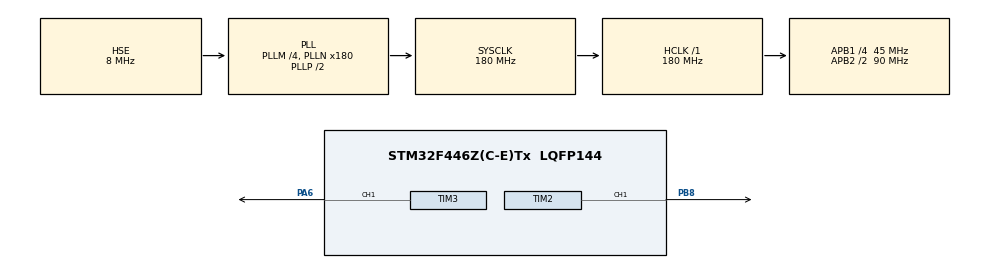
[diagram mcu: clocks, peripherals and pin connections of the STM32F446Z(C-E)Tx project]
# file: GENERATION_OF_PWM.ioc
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Mcu.Family=STM32F4
Mcu.Name=STM32F446Z(C-E)Tx
Mcu.Package=LQFP144
NVIC.PriorityGroup=NVIC_PRIORITYGROUP_4
PA6.Signal=S_TIM3_CH1
PB8.Signal=S_TIM2_CH1_ETR
PH0-OSC_IN.Mode=HSE-External-Oscillator
PH0-OSC_IN.Signal=RCC_OSC_IN
PH1-OSC_OUT.Mode=HSE-External-Oscillator
PH1-OSC_OUT.Signal=RCC_OSC_OUT
ProjectManager.HeapSize=0x200
ProjectManager.StackSize=0x400
ProjectManager.TargetToolchain=STM32CubeIDE
RCC.AHBFreq_Value=180000000
RCC.APB1CLKDivider=RCC_HCLK_DIV4
RCC.APB1Freq_Value=45000000
RCC.APB1TimFreq_Value=90000000
RCC.APB2CLKDivider=RCC_HCLK_DIV2
RCC.APB2Freq_Value=90000000
RCC.APB2TimFreq_Value=180000000
RCC.CortexFreq_Value=180000000
RCC.HCLKFreq_Value=180000000
RCC.HSE_VALUE=8000000
RCC.PLLM=4
RCC.PLLN=180
RCC.PLLSourceVirtual=RCC_PLLSOURCE_HSE
RCC.SYSCLKFreq_VALUE=180000000
RCC.SYSCLKSource=RCC_SYSCLKSOURCE_PLLCLK
RCC.USBFreq_Value=180000000
RCC.VCOOutputFreq_Value=360000000
SH.S_TIM2_CH1_ETR.0=TIM2_CH1,PWM Generation1 CH1
SH.S_TIM3_CH1.0=TIM3_CH1,PWM Generation1 CH1
TIM2.Channel-PWM\ Generation1\ CH1=TIM_CHANNEL_1
TIM2.Period=999
TIM2.Prescaler=179
TIM3.Channel-PWM\ Generation1\ CH1=TIM_CHANNEL_1
TIM3.Period=999
TIM3.Prescaler=179
VP_TIM2_VS_ClockSourceINT.Mode=Internal
VP_TIM3_VS_ClockSourceINT.Mode=Internal
board=custom

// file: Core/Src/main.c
/* USER CODE BEGIN Header */
/**
  ******************************************************************************
  * @file           : main.c
  * @brief          : Main program body
  ******************************************************************************
  * @attention
  *
  * Copyright (c) 2026 STMicroelectronics.
  * All rights reserved.
  *
  * This software is licensed under terms that can be found in the LICENSE file
  * in the root directory of this software component.
  * If no LICENSE file comes with this software, it is provided AS-IS.
  *
  ******************************************************************************
  */
/* USER CODE END Header */
#include "main.h"

TIM_HandleTypeDef htim2;
TIM_HandleTypeDef htim3;

/* USER CODE BEGIN PV */
int j;
/* USER CODE END PV */

void SystemClock_Config(void);
static void MX_GPIO_Init(void);
static void MX_TIM2_Init(void);
static void MX_TIM3_Init(void);

/* USER CODE BEGIN 0 */

	void Rotation(int i)
	{
		if(i>=0)
		{
			TIM2->CCR1 = i;
			TIM3->CCR1 = 0;
		}
		else
		{
			TIM3->CCR1 = 0;
			TIM3->CCR1 = -i;
		}
	}

/* USER CODE END 0 */

int main(void)
{

  /* MCU Configuration--------------------------------------------------------*/

  /* Reset of all peripherals, Initializes the Flash interface and the Systick. */
  HAL_Init();

  /* Configure the system clock */
  SystemClock_Config();

  /* Initialize all configured peripherals */
  MX_GPIO_Init();
  MX_TIM2_Init();
  MX_TIM3_Init();
  /* USER CODE BEGIN 2 */
	  HAL_TIM_PWM_Start(&htim2, TIM_CHANNEL_1);
	  HAL_TIM_PWM_Start(&htim3, TIM_CHANNEL_1);

  /* USER CODE END 2 */

  /* Infinite loop */
  while (1)
  {

    /* USER CODE BEGIN 3 */
	  Rotation(-100);
	  HAL_Delay(1000);
	  Rotation(100);
	  HAL_Delay(1000);
	  Rotation(0);
	  HAL_Delay(1000);
  }
  /* USER CODE END 3 */
}

void SystemClock_Config(void)
{
  RCC_OscInitTypeDef RCC_OscInitStruct = {0};
  RCC_ClkInitTypeDef RCC_ClkInitStruct = {0};

  /** Configure the main internal regulator output voltage
  */
  __HAL_RCC_PWR_CLK_ENABLE();
  __HAL_PWR_VOLTAGESCALING_CONFIG(PWR_REGULATOR_VOLTAGE_SCALE1);

  /** Initializes the RCC Oscillators according to the specified parameters
  * in the RCC_OscInitTypeDef structure.
  */
  RCC_OscInitStruct.OscillatorType = RCC_OSCILLATORTYPE_HSE;
  RCC_OscInitStruct.HSEState = RCC_HSE_ON;
  RCC_OscInitStruct.PLL.PLLState = RCC_PLL_ON;
  RCC_OscInitStruct.PLL.PLLSource = RCC_PLLSOURCE_HSE;
  RCC_OscInitStruct.PLL.PLLM = 4;
  RCC_OscInitStruct.PLL.PLLN = 180;
  RCC_OscInitStruct.PLL.PLLP = RCC_PLLP_DIV2;
  RCC_OscInitStruct.PLL.PLLQ = 2;
  RCC_OscInitStruct.PLL.PLLR = 2;
  if (HAL_RCC_OscConfig(&RCC_OscInitStruct) != HAL_OK)
  {
    Error_Handler();
  }

  /** Activate the Over-Drive mode
  */
  if (HAL_PWREx_EnableOverDrive() != HAL_OK)
  {
    Error_Handler();
  }

  /** Initializes the CPU, AHB and APB buses clocks
  */
  RCC_ClkInitStruct.ClockType = RCC_CLOCKTYPE_HCLK|RCC_CLOCKTYPE_SYSCLK
                              |RCC_CLOCKTYPE_PCLK1|RCC_CLOCKTYPE_PCLK2;
  RCC_ClkInitStruct.SYSCLKSource = RCC_SYSCLKSOURCE_PLLCLK;
  RCC_ClkInitStruct.AHBCLKDivider = RCC_SYSCLK_DIV1;
  RCC_ClkInitStruct.APB1CLKDivider = RCC_HCLK_DIV4;
  RCC_ClkInitStruct.APB2CLKDivider = RCC_HCLK_DIV2;

  if (HAL_RCC_ClockConfig(&RCC_ClkInitStruct, FLASH_LATENCY_5) != HAL_OK)
  {
    Error_Handler();
  }
}

static void MX_TIM2_Init(void)
{

  TIM_ClockConfigTypeDef sClockSourceConfig = {0};
  TIM_MasterConfigTypeDef sMasterConfig = {0};
  TIM_OC_InitTypeDef sConfigOC = {0};

  htim2.Instance = TIM2;
  htim2.Init.Prescaler = 179;
  htim2.Init.CounterMode = TIM_COUNTERMODE_UP;
  htim2.Init.Period = 999;
  htim2.Init.ClockDivision = TIM_CLOCKDIVISION_DIV1;
  htim2.Init.AutoReloadPreload = TIM_AUTORELOAD_PRELOAD_DISABLE;
  if (HAL_TIM_Base_Init(&htim2) != HAL_OK)
  {
    Error_Handler();
  }
  sClockSourceConfig.ClockSource = TIM_CLOCKSOURCE_INTERNAL;
  if (HAL_TIM_ConfigClockSource(&htim2, &sClockSourceConfig) != HAL_OK)
  {
    Error_Handler();
  }
  if (HAL_TIM_PWM_Init(&htim2) != HAL_OK)
  {
    Error_Handler();
  }
  sMasterConfig.MasterOutputTrigger = TIM_TRGO_RESET;
  sMasterConfig.MasterSlaveMode = TIM_MASTERSLAVEMODE_DISABLE;
  if (HAL_TIMEx_MasterConfigSynchronization(&htim2, &sMasterConfig) != HAL_OK)
  {
    Error_Handler();
  }
  sConfigOC.OCMode = TIM_OCMODE_PWM1;
  sConfigOC.Pulse = 0;
  sConfigOC.OCPolarity = TIM_OCPOLARITY_HIGH;
  sConfigOC.OCFastMode = TIM_OCFAST_DISABLE;
  if (HAL_TIM_PWM_ConfigChannel(&htim2, &sConfigOC, TIM_CHANNEL_1) != HAL_OK)
  {
    Error_Handler();
  }
  HAL_TIM_MspPostInit(&htim2);

}

static void MX_TIM3_Init(void)
{

  TIM_ClockConfigTypeDef sClockSourceConfig = {0};
  TIM_MasterConfigTypeDef sMasterConfig = {0};
  TIM_OC_InitTypeDef sConfigOC = {0};

  htim3.Instance = TIM3;
  htim3.Init.Prescaler = 179;
  htim3.Init.CounterMode = TIM_COUNTERMODE_UP;
  htim3.Init.Period = 999;
  htim3.Init.ClockDivision = TIM_CLOCKDIVISION_DIV1;
  htim3.Init.AutoReloadPreload = TIM_AUTORELOAD_PRELOAD_DISABLE;
  if (HAL_TIM_Base_Init(&htim3) != HAL_OK)
  {
    Error_Handler();
  }
  sClockSourceConfig.ClockSource = TIM_CLOCKSOURCE_INTERNAL;
  if (HAL_TIM_ConfigClockSource(&htim3, &sClockSourceConfig) != HAL_OK)
  {
    Error_Handler();
  }
  if (HAL_TIM_PWM_Init(&htim3) != HAL_OK)
  {
    Error_Handler();
  }
  sMasterConfig.MasterOutputTrigger = TIM_TRGO_RESET;
  sMasterConfig.MasterSlaveMode = TIM_MASTERSLAVEMODE_DISABLE;
  if (HAL_TIMEx_MasterConfigSynchronization(&htim3, &sMasterConfig) != HAL_OK)
  {
    Error_Handler();
  }
  sConfigOC.OCMode = TIM_OCMODE_PWM1;
  sConfigOC.Pulse = 0;
  sConfigOC.OCPolarity = TIM_OCPOLARITY_HIGH;
  sConfigOC.OCFastMode = TIM_OCFAST_DISABLE;
  if (HAL_TIM_PWM_ConfigChannel(&htim3, &sConfigOC, TIM_CHANNEL_1) != HAL_OK)
  {
    Error_Handler();
  }
  HAL_TIM_MspPostInit(&htim3);

}

static void MX_GPIO_Init(void)
{

  /* GPIO Ports Clock Enable */
  __HAL_RCC_GPIOH_CLK_ENABLE();
  __HAL_RCC_GPIOA_CLK_ENABLE();
  __HAL_RCC_GPIOB_CLK_ENABLE();

}

void Error_Handler(void)
{
  __disable_irq();
  while (1)
  {
  }
}
